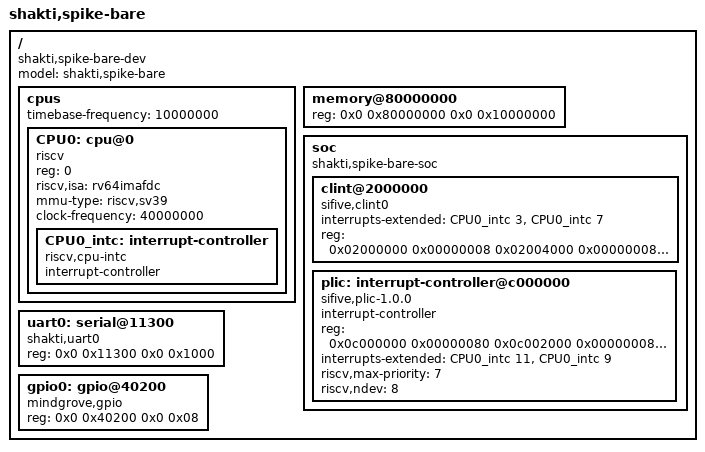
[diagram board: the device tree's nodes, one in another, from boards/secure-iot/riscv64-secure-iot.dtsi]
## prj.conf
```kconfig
CONFIG_GPIO=y
CONFIG_GPIO_MINDGROVE=y
CONFIG_NUM_IRQ_PRIO_LEVELS=7
# CONFIG_ARCH_HAS_BIG_VECTOR_TABLE=y 
CONFIG_NUM_IRQS=256
CONFIG_MULTITHREADING=y
CONFIG_TICKLESS_KERNEL=y
CONFIG_MULTI_LEVEL_INTERRUPTS=y
CONFIG_2ND_LEVEL_INTERRUPTS=y
CONFIG_NUM_2ND_LEVEL_AGGREGATORS=1
CONFIG_2ND_LVL_INTR_00_OFFSET=11
CONFIG_MAIN_STACK_SIZE=4096
CONFIG_ISR_STACK_SIZE=2048  
CONFIG_LOG=y
CONFIG_LOG_BACKEND_UART=y
CONFIG_THREAD_STACK_INFO=y
CONFIG_SYS_HEAP_ALLOC_LOOPS=0
CONFIG_PRINTK=y
# CONFIG_PLIC=y
# CONFIG_NUM_IRQS=256
```

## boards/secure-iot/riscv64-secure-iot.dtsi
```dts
/ {
#address-cells = <2>;
#size-cells = <2>;
  compatible = "shakti,spike-bare-dev";
  model = "shakti,spike-bare";
  cpus {
#address-cells = <1>;
#size-cells = <0>;
    timebase-frequency = <10000000>;
CPU0: cpu@0 {
        device_type = "cpu";
        reg = <0>;
        status = "okay";
        compatible = "riscv";
        riscv,isa = "rv64imafdc";
        mmu-type = "riscv,sv39";
        clock-frequency = <40000000>;
CPU0_intc: interrupt-controller {
             #address-cells = <0>;
	           #interrupt-cells = <1>;
             interrupt-controller;
             compatible = "riscv,cpu-intc";
           };
      };
  };
  memory@80000000 {
    device_type = "memory";
    reg = <0x0 0x80000000 0x0 0x10000000 >;
  };
  soc {
    #address-cells = <1>;
		#size-cells = <1>;
    compatible = "shakti,spike-bare-soc", "simple-bus";
    ranges;
    clint@2000000 {
      #address-cells = <0>;
      #size-cells = <2>;
      compatible = "sifive,clint0";
      interrupts-extended = <&CPU0_intc 3 &CPU0_intc 7 >;
      reg = <0x02000000 0x00000008
            0x02004000 0x00000008
	    0x0200bff8 0x00000008>;
    };
    plic: interrupt-controller@c000000 {
      #address-cells = <0>;
			#interrupt-cells = <2>;
      compatible = "sifive,plic-1.0.0";
      interrupt-controller;
      reg = <0x0c000000 0x00000080
			       0x0c002000 0x00000008
			       0x0c200000 0x00001000>;
			reg-names = "prio", "irq_en", "reg";
      interrupts-extended = <&CPU0_intc 11 &CPU0_intc 9>; //11 as to mention MACHINE MODE for CPU or 9 for SUPERVISOR MODE for CPU...
      riscv,max-priority = <7>;
      riscv,ndev = <8>;
    };
  };

uart0: serial@11300 {
         compatible = "shakti,uart0";
         reg= < 0x0 0x11300 0x0 0x1000>;
  };

gpio0: gpio@40200 {
          compatible = "mindgrove,gpio";
          reg = < 0x0 0x40200 0x0 0x08>;
  };
};
```

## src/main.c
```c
#include <zephyr/kernel.h>
#include <zephyr/device.h>
#include <zephyr/devicetree.h>
#include <zephyr/drivers/gpio.h>
#include <stdio.h>

/* Use DT_NODELABEL to get the node ID for the GPIO controller defined as 'gpio0' in DTS */
#define GPIO_NODE DT_NODELABEL(gpio0)

// Check if the node label is available and defined
#if !DT_NODE_HAS_STATUS(GPIO_NODE, okay)
#error "Devicetree node label 'gpio0' not found or disabled in DTS."
#endif

void main(void)
{
    // Get the device structure for the GPIO controller
    const struct device *dev = DEVICE_DT_GET(GPIO_NODE); 
    int ret;
    
    if (!device_is_ready(dev)) {
        printf("Error: GPIO device %s is not ready.\n", dev->name);
        return;
    }

    // Configure Pin 0, 1, and 2 as Outputs, initialized Low
    
    // Configure Pin 0
    ret = gpio_pin_configure(dev, 0, GPIO_OUTPUT | GPIO_OUTPUT_INIT_LOW);
    if (ret < 0) {
        printf("Error configuring Pin 0: %d\n", ret);
        return;
    }

    // Configure Pin 1
    ret = gpio_pin_configure(dev, 1, GPIO_OUTPUT | GPIO_OUTPUT_INIT_LOW);
    if (ret < 0) {
        printf("Error configuring Pin 1: %d\n", ret);
        return;
    }

    // Configure Pin 2
    ret = gpio_pin_configure(dev, 2, GPIO_OUTPUT | GPIO_OUTPUT_INIT_LOW);
    if (ret < 0) {
        printf("Error configuring Pin 2: %d\n", ret);
        return;
    }

    printf("GPIO Output Toggle Test (Pins 0, 1, 2) Starting...\n");

    while (1) {
        // Toggle the state of all three pins simultaneously
        printf("Toggle...\n");
        ret = gpio_port_toggle_bits(dev, BIT(0) | BIT(1) | BIT(2));
        if (ret < 0) {
            printf("Error toggling pins: %d\n", ret);
        }
        
        k_msleep(500);
    }
}
```
